AUTOSAR XML (schema 4-0-3)
standard types defined: Boolean, UInt16, UInt32, UInt8
package /AUTOSAR_Platform/DataConstrs
  range DC_Boolean: raw 0..1
  range DC_UInt16: raw 0..65535
  range DC_UInt8: raw 0..255
package /PATAC/MSM/ComponentTypes
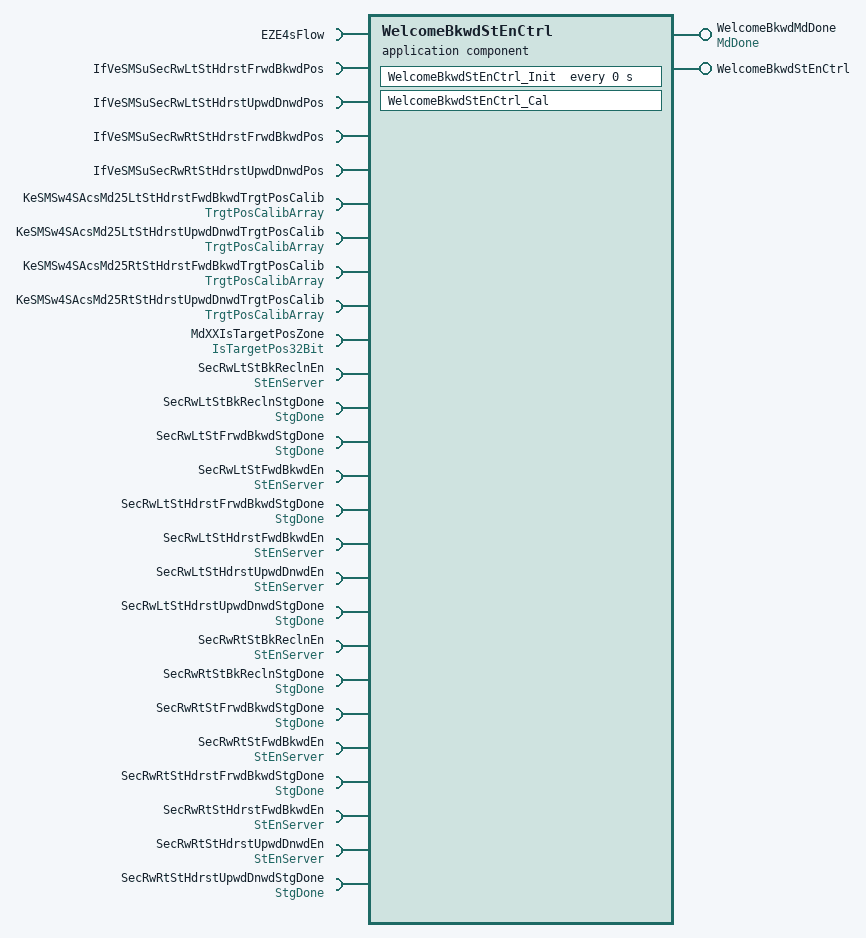
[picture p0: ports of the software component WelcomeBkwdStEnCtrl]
  application sw component type WelcomeBkwdStEnCtrl
    provide port WelcomeBkwdMdDone: nonqueued-sender-com-spec{data-element=MdDone/Val, init-value=0}, provided-interface=MdDone
    provide port WelcomeBkwdStEnCtrl: server-com-spec{operation=WelcomeBkwdStEnCtrl/Cal, queue-length=1}, provided-interface=WelcomeBkwdStEnCtrl
    26 x require port:
      EZE4sFlow: client-com-spec=EZE4sFlow/Cal, required-interface=EZE4sFlow
      IfVeSMSuSecRwLtStHdrstFrwdBkwdPos: nonqueued-receiver-com-spec{data-element=IfVeSMSuSecRwLtStHdrstFrwdBkwdPos/Val, filter=data-filter-type=ALWAYS, init-value=0}, required-interface=IfVeSMSuSecRwLtStHdrstFrwdBkwdPos
      IfVeSMSuSecRwLtStHdrstUpwdDnwdPos: nonqueued-receiver-com-spec{data-element=IfVeSMSuSecRwLtStHdrstUpwdDnwdPos/Val, filter=data-filter-type=ALWAYS, init-value=0}, required-interface=IfVeSMSuSecRwLtStHdrstUpwdDnwdPos
      IfVeSMSuSecRwRtStHdrstFrwdBkwdPos: nonqueued-receiver-com-spec{data-element=IfVeSMSuSecRwRtStHdrstFrwdBkwdPos/Val, filter=data-filter-type=ALWAYS, init-value=0}, required-interface=IfVeSMSuSecRwRtStHdrstFrwdBkwdPos
      IfVeSMSuSecRwRtStHdrstUpwdDnwdPos: nonqueued-receiver-com-spec{data-element=IfVeSMSuSecRwRtStHdrstUpwdDnwdPos/Val, filter=data-filter-type=ALWAYS, init-value=0}, required-interface=IfVeSMSuSecRwRtStHdrstUpwdDnwdPos
      KeSMSw4SAcsMd25LtStHdrstFwdBkwdTrgtPosCalib: nonqueued-receiver-com-spec{data-element=TrgtPosArray, filter=data-filter-type=ALWAYS, init-value=[4095, 4095, 4095]}, required-interface=TrgtPosCalibArray
      KeSMSw4SAcsMd25LtStHdrstUpwdDnwdTrgtPosCalib: nonqueued-receiver-com-spec{data-element=TrgtPosArray, filter=data-filter-type=ALWAYS, init-value=[4095, 4095, 4095]}, required-interface=TrgtPosCalibArray
      KeSMSw4SAcsMd25RtStHdrstFwdBkwdTrgtPosCalib: nonqueued-receiver-com-spec{data-element=TrgtPosArray, filter=data-filter-type=ALWAYS, init-value=[4095, 4095, 4095]}, required-interface=TrgtPosCalibArray
      KeSMSw4SAcsMd25RtStHdrstUpwdDnwdTrgtPosCalib: nonqueued-receiver-com-spec{data-element=TrgtPosArray, filter=data-filter-type=ALWAYS, init-value=[4095, 4095, 4095]}, required-interface=TrgtPosCalibArray
      MdXXIsTargetPosZone: nonqueued-receiver-com-spec{data-element=IsTargetPos32Bit/Val, filter=data-filter-type=ALWAYS, init-value=0}, required-interface=IsTargetPos32Bit
      SecRwLtStBkReclnEn: required-com-specs=[Clear, Get, Set], required-interface=StEnServer
      SecRwLtStBkReclnStgDone: nonqueued-receiver-com-spec{data-element=StgDone/Val, filter=data-filter-type=ALWAYS, init-value=0}, required-interface=StgDone
      SecRwLtStFrwdBkwdStgDone: nonqueued-receiver-com-spec{data-element=StgDone/Val, filter=data-filter-type=ALWAYS, init-value=0}, required-interface=StgDone
      SecRwLtStFwdBkwdEn: required-com-specs=[Clear, Get, Set], required-interface=StEnServer
      SecRwLtStHdrstFrwdBkwdStgDone: nonqueued-receiver-com-spec{data-element=StgDone/Val, filter=data-filter-type=ALWAYS, init-value=0}, required-interface=StgDone
      SecRwLtStHdrstFwdBkwdEn: required-com-specs=[Clear, Get, Set], required-interface=StEnServer
      SecRwLtStHdrstUpwdDnwdEn: required-com-specs=[Clear, Get, Set], required-interface=StEnServer
      SecRwLtStHdrstUpwdDnwdStgDone: nonqueued-receiver-com-spec{data-element=StgDone/Val, filter=data-filter-type=ALWAYS, init-value=0}, required-interface=StgDone
      SecRwRtStBkReclnEn: required-com-specs=[Clear, Get, Set], required-interface=StEnServer
      SecRwRtStBkReclnStgDone: nonqueued-receiver-com-spec{data-element=StgDone/Val, filter=data-filter-type=ALWAYS, init-value=0}, required-interface=StgDone
      SecRwRtStFrwdBkwdStgDone: nonqueued-receiver-com-spec{data-element=StgDone/Val, filter=data-filter-type=ALWAYS, init-value=0}, required-interface=StgDone
      SecRwRtStFwdBkwdEn: required-com-specs=[Clear, Get, Set], required-interface=StEnServer
      SecRwRtStHdrstFrwdBkwdStgDone: nonqueued-receiver-com-spec{data-element=StgDone/Val, filter=data-filter-type=ALWAYS, init-value=0}, required-interface=StgDone
      SecRwRtStHdrstFwdBkwdEn: required-com-specs=[Clear, Get, Set], required-interface=StEnServer
      SecRwRtStHdrstUpwdDnwdEn: required-com-specs=[Clear, Get, Set], required-interface=StEnServer
      SecRwRtStHdrstUpwdDnwdStgDone: nonqueued-receiver-com-spec{data-element=StgDone/Val, filter=data-filter-type=ALWAYS, init-value=0}, required-interface=StgDone
    behavior WelcomeBkwdStEnCtrl_InternalBehavior
      operation invoked event OIT_WelcomeBkwdStEnCtrl_Cal_WelcomeBkwdStEnCtrl_Cal: start-on-event=WelcomeBkwdStEnCtrl_Cal, operation=WelcomeBkwdStEnCtrl.Cal
      timing event WelcomeBkwdStEnCtrl_InitEvent: start-on-event=WelcomeBkwdStEnCtrl_Init, period=0
      runnable WelcomeBkwdStEnCtrl_Cal
        data-receive-point-by-arguments:
          17 x access:
            REC_IfVeSMSuSecRwLtStHdrstFrwdBkwdPos_Val: accessed-variable=IfVeSMSuSecRwLtStHdrstFrwdBkwdPos.Val
            REC_IfVeSMSuSecRwLtStHdrstUpwdDnwdPos_Val: accessed-variable=IfVeSMSuSecRwLtStHdrstUpwdDnwdPos.Val
            REC_IfVeSMSuSecRwRtStHdrstFrwdBkwdPos_Val: accessed-variable=IfVeSMSuSecRwRtStHdrstFrwdBkwdPos.Val
            REC_IfVeSMSuSecRwRtStHdrstUpwdDnwdPos_Val: accessed-variable=IfVeSMSuSecRwRtStHdrstUpwdDnwdPos.Val
            REC_KeSMSw4SAcsMd21HdrstFwdBkwdTrgtPosCalib_TrgtPosArray: accessed-variable=KeSMSw4SAcsMd25LtStHdrstFwdBkwdTrgtPosCalib.TrgtPosArray
            REC_KeSMSw4SAcsMd21HdrstUpwdDnwdTrgtPosCalib_TrgtPosArray: accessed-variable=KeSMSw4SAcsMd25LtStHdrstUpwdDnwdTrgtPosCalib.TrgtPosArray
            REC_KeSMSw4SAcsMd23HdrstFwdBkwdTrgtPosCalib_TrgtPosArray: accessed-variable=KeSMSw4SAcsMd25RtStHdrstFwdBkwdTrgtPosCalib.TrgtPosArray
            REC_KeSMSw4SAcsMd23HdrstUpwdDnwdTrgtPosCalib_TrgtPosArray: accessed-variable=KeSMSw4SAcsMd25RtStHdrstUpwdDnwdTrgtPosCalib.TrgtPosArray
            REC_MdXXIsTargetPosZone_Val: accessed-variable=MdXXIsTargetPosZone.Val
            REC_SecRwLtStBkReclnStgDone_Val: accessed-variable=SecRwLtStBkReclnStgDone.Val
            REC_SecRwLtStFrwdBkwdStgDone_Val: accessed-variable=SecRwLtStFrwdBkwdStgDone.Val
            REC_SecRwLtStHdrstFrwdBkwdStgDone_Val: accessed-variable=SecRwLtStHdrstFrwdBkwdStgDone.Val
            REC_SecRwLtStHdrstUpwdDnwdStgDone_Val: accessed-variable=SecRwLtStHdrstUpwdDnwdStgDone.Val
            REC_SecRwRtStBkReclnStgDone_Val: accessed-variable=SecRwRtStBkReclnStgDone.Val
            REC_SecRwRtStFrwdBkwdStgDone_Val: accessed-variable=SecRwRtStFrwdBkwdStgDone.Val
            REC_SecRwRtStHdrstFrwdBkwdStgDone_Val: accessed-variable=SecRwRtStHdrstFrwdBkwdStgDone.Val
            REC_SecRwRtStHdrstUpwdDnwdStgDone_Val: accessed-variable=SecRwRtStHdrstUpwdDnwdStgDone.Val
        data-send-points:
          access SEND_WelcomeBkwdMdDone_Val: accessed-variable=WelcomeBkwdMdDone.Val
        17 x sync call, all with timeout=0:
          SC_EZE4sFlow_Cal: operation=EZE4sFlow.Cal
          SC_SecRwLtStBkReclnEn_Clear: operation=SecRwLtStBkReclnEn.Clear
          SC_SecRwLtStBkReclnEn_Set: operation=SecRwLtStBkReclnEn.Set
          SC_SecRwLtStFwdBkwdEn_Clear: operation=SecRwLtStFwdBkwdEn.Clear
          SC_SecRwLtStFwdBkwdEn_Set: operation=SecRwLtStFwdBkwdEn.Set
          SC_SecRwLtStHdrstFwdBkwdEn_Clear: operation=SecRwLtStHdrstFwdBkwdEn.Clear
          SC_SecRwLtStHdrstFwdBkwdEn_Set: operation=SecRwLtStHdrstFwdBkwdEn.Set
          SC_SecRwLtStHdrstUpwdDnwdEn_Clear: operation=SecRwLtStHdrstUpwdDnwdEn.Clear
          SC_SecRwLtStHdrstUpwdDnwdEn_Set: operation=SecRwLtStHdrstUpwdDnwdEn.Set
          SC_SecRwRtStBkReclnEn_Clear: operation=SecRwRtStBkReclnEn.Clear
          SC_SecRwRtStBkReclnEn_Set: operation=SecRwRtStBkReclnEn.Set
          SC_SecRwRtStFwdBkwdEn_Clear: operation=SecRwRtStFwdBkwdEn.Clear
          SC_SecRwRtStFwdBkwdEn_Set: operation=SecRwRtStFwdBkwdEn.Set
          SC_SecRwRtStHdrstFwdBkwdEn_Clear: operation=SecRwRtStHdrstFwdBkwdEn.Clear
          SC_SecRwRtStHdrstFwdBkwdEn_Set: operation=SecRwRtStHdrstFwdBkwdEn.Set
          SC_SecRwRtStHdrstUpwdDnwdEn_Clear: operation=SecRwRtStHdrstUpwdDnwdEn.Clear
          SC_SecRwRtStHdrstUpwdDnwdEn_Set: operation=SecRwRtStHdrstUpwdDnwdEn.Set
      runnable WelcomeBkwdStEnCtrl_Init
  swc implementation WelcomeBkwdStEnCtrl_Implementation: behavior=WelcomeBkwdStEnCtrl_InternalBehavior
    code-descriptors:
      code Default: artifact-descriptors=autosar-engineering-object={short-label=Default, category=SWSRC}
package /PATAC/MSM/ModeAdjust/DataType
  impl type TrgtPosCalibArray: category=ARRAY, sw-calibration-access=READ-ONLY, type-emitter=RTE  # 0:pos 1:max 2:min
    element Element: array-size=3, array-size-semantics=FIXED-SIZE, implementation-data-type=UInt16, invalid-value=0
package /PATAC/MSM/ModeAdjust/PortInterface
  client server interface EZE4sFlow
    operation Cal
      9 x arg, all with server-argument-impl-policy=USE-ARGUMENT-TYPE:
        BkReclnStgDone: type=Implementation/Boolean, direction=IN
        HdrstUpwdDnwdStgDone: type=Implementation/Boolean, direction=IN
        HdrstFrwdBkwdStgDone: type=Implementation/Boolean, direction=IN
        SecRwStFrwdBkwdStgDone: type=DataTypes/Boolean, direction=IN
        Chkhdflg: type=Implementation/Boolean, direction=IN
        BkReclnEn: type=Implementation/Boolean, direction=OUT
        HdrstUpwdEn: type=Implementation/Boolean, direction=OUT
        HdrstFrwdEn: type=Implementation/Boolean, direction=OUT
        SecRwStFrwdBkwdEn: type=DataTypes/Boolean, direction=OUT
  client server interface StEnServer
    operation Clear
      arg data: type=UInt8, direction=IN, server-argument-impl-policy=USE-ARGUMENT-TYPE
    operation Get
      arg data: type=UInt32, direction=OUT, server-argument-impl-policy=USE-ARGUMENT-TYPE
    operation Set
      arg data: type=UInt8, direction=IN, server-argument-impl-policy=USE-ARGUMENT-TYPE
  client server interface WelcomeBkwdStEnCtrl
    operation Cal
  4 x sender receiver interface:
    IsTargetPos32Bit: invalidation-policy{data-element=IsTargetPos32Bit/Val, handle-invalid=DONT-INVALIDATE}
      data Val: type=UInt32
    MdDone: invalidation-policy{data-element=MdDone/Val, handle-invalid=DONT-INVALIDATE}
      data Val: type=UInt8
    StgDone: invalidation-policy{data-element=StgDone/Val, handle-invalid=DONT-INVALIDATE}
      data Val: type=Implementation/Boolean
    TrgtPosCalibArray: invalidation-policy{data-element=TrgtPosArray, handle-invalid=DONT-INVALIDATE}
      data TrgtPosArray: type=TrgtPosCalibArray  # 0:Pos 1:Max 2:Min
package /PATAC/MSM/PortInterfaces
  4 x sender receiver interface:
    IfVeSMSuSecRwLtStHdrstFrwdBkwdPos: invalidation-policy{data-element=IfVeSMSuSecRwLtStHdrstFrwdBkwdPos/Val, handle-invalid=DONT-INVALIDATE}
      data Val: type=UInt16
    IfVeSMSuSecRwLtStHdrstUpwdDnwdPos: invalidation-policy{data-element=IfVeSMSuSecRwLtStHdrstUpwdDnwdPos/Val, handle-invalid=DONT-INVALIDATE}
      data Val: type=UInt16
    IfVeSMSuSecRwRtStHdrstFrwdBkwdPos: invalidation-policy{data-element=IfVeSMSuSecRwRtStHdrstFrwdBkwdPos/Val, handle-invalid=DONT-INVALIDATE}
      data Val: type=UInt16
    IfVeSMSuSecRwRtStHdrstUpwdDnwdPos: invalidation-policy{data-element=IfVeSMSuSecRwRtStHdrstUpwdDnwdPos/Val, handle-invalid=DONT-INVALIDATE}
      data Val: type=UInt16
